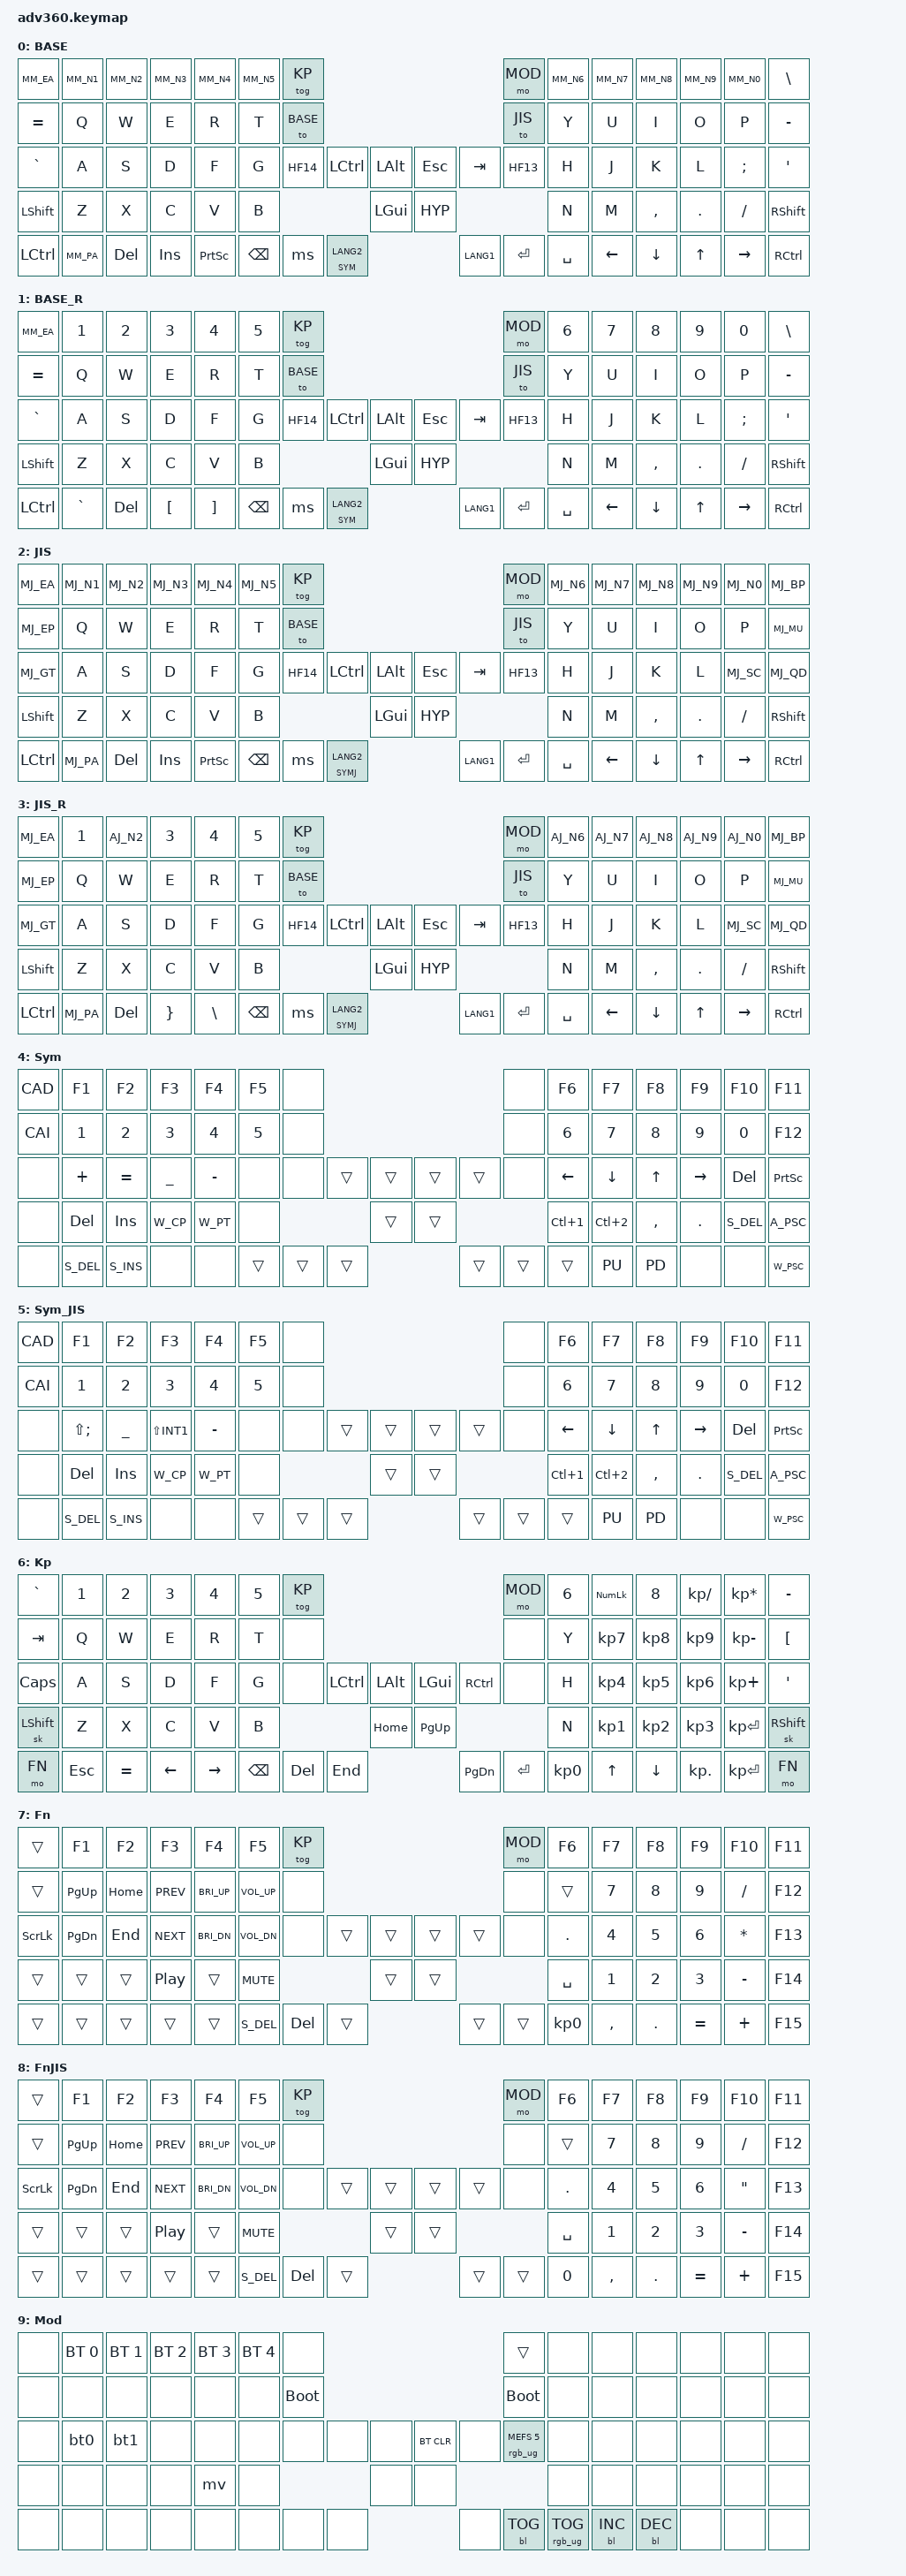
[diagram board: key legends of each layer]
#include <behaviors.dtsi>
#include <dt-bindings/zmk/keys.h>
#include <dt-bindings/zmk/bt.h>
#include <dt-bindings/zmk/rgb.h>
#include <dt-bindings/zmk/stp.h>
#include <dt-bindings/zmk/backlight.h>
#include <dt-bindings/zmk/pointing.h>

#include "include/adv360.h"
#include "include/helper.h"
#include "ansi-jis.dtsi"

#define BASE  0
#define BREV  1
#define JIS   2
#define JREV  3
#define SYM   4
#define SYMJ  5
#define KP    6
#define FN    7
#define FNJ   8
#define MOD   9

#define LCS LC(LSHFT)
#define RCS RC(RSHFT)
#define LCA LC(LALT)
#define RCA RC(RALT)
#define HYP LG(LA(LCTRL))
#define MEH LA(LS(LCTRL))
#define CAD LC(LA(DEL))
#define CAI LC(LA(INS))
#define ST  LG(TAB)
#define GG  LG(GRAVE)
#define HF13 LG(LA(LC(F13)))
#define HF14 LG(LA(LC(F14)))
#define W_CP LC(INS)
#define W_PT LS(INS)
#define C_PD LC(PG_DN)
#define C_PU LC(PG_UP)
#define A_PSC LA(PSCRN)
#define W_PSC LG(PSCRN)
#define S_DEL LS(DEL)
#define S_INS LS(INS)

#define BT0 &bt BT_SEL 0
#define BT1 &bt BT_SEL 1
#define BT2 &bt BT_SEL 2
#define BT3 &bt BT_SEL 3
#define BT4 &bt BT_SEL 4

#define XXX &none
#define ___ &trans

#define JRBR BSLS
#define JLBR RBRC

/* Global defaults */

#define QUICK_TAP_MS 175

&sk {
  release-after-ms = <200>;
  quick-release;
};

&sl { // Allow sticky mods to chord across sticky layers.
  ignore-modifiers;
};

&lt {
  flavor = "balanced";
  tapping-term-ms = <200>;
  // quick-tap-ms = <QUICK_TAP_MS>;
};

/* Magic-shift & auto-layers */

// Tap: repeat after alpha, else sticky-shift |
// Shift + tap/ double-tap: caps-word | Hold: shift.
/* #define ms &magic_shift LSHFT 0 */
/* ZMK_HOLD_TAP(magic_shift, bindings = <&kp>, <&magic_shift_tap>; */
/*              flavor = "balanced"; tapping-term-ms = <200>; */
/*              quick-tap-ms = <QUICK_TAP_MS>;) */
/* ZMK_MOD_MORPH(magic_shift_tap, bindings = <&shift_repeat>, <&caps_word>; */
/*               mods = <(MOD_LSFT)>;) */
/* ZMK_ADAPTIVE_KEY( */
/*     shift_repeat, bindings = <&sk LSHFT>; */
/*     repeat { */
/*       trigger-keys = <A B C D E F G H I J K L M N O P Q R S T U V W X Y Z 1 2 3 4 5 6 7 8 9>; */
/*       bindings = <&key_repeat>; */
/*       max-prior-idle-ms = <1200>; */
/*       strict-modifiers; */
/*     };) */
&caps_word { // Mods deactivate caps-word, requires PR #1451. [TODO: rebase]
  /delete-property/ ignore-modifiers;
  continue-list = <UNDERSCORE MINUS LS(INT1) BACKSPACE DELETE>;
};

/ {
    behaviors {
      #include "macros.dtsi"
      #include "version.dtsi"
      #include "switch_bt.dtsi"
      
      mv: macro_version {
        compatible = "zmk,behavior-macro";
        #binding-cells = <0>;
        bindings = <&kp RET>;
      };

      hm: homerow_mods {
          compatible = "zmk,behavior-hold-tap";
          #binding-cells = <2>;
          tapping-term-ms = <200>;
          quick_tap_ms = <180>;
          flavor = "tap-preferred";
          bindings = <&kp>, <&kp>;
      };

      ms: magic_shift {
        compatible = "zmk,behavior-tap-dance";
        #binding-cells = <0>;
        tapping-term-ms = <200>;
        bindings = <&sk LSHFT>, <&caps_word>;
      };

    };

    keymap {
        compatible = "zmk,keymap";

        default_layer {
          display-name = "BASE";
          bindings = <
            MM_EA     MM_N1 MM_N2   MM_N3    MM_N4     MM_N5 &tog KP                                                                 &mo MOD  MM_N6 MM_N7    MM_N8     MM_N9    MM_N0     &kp BSLH
            &kp EQUAL &kp Q &kp W   &kp E    &kp R     &kp T &to BASE                                                                &to JIS  &kp Y &kp U    &kp I     &kp O    &kp P     &kp MINUS
            &kp GRAVE &kp A &kp S   &kp D    &kp F     &kp G &kp HF14          &kp LCTRL &kp LALT      &kp ESC   &kp TAB             &kp HF13 &kp H &kp J    &kp K     &kp L    &kp SEMI  &kp SQT
            &kp LSHFT &kp Z &kp X   &kp C    &kp V     &kp B                             &kp LGUI      &kp HYP                                &kp N &kp M    &kp COMMA &kp DOT  &kp FSLH  &kp RSHFT
            &kp LCTRL MM_PA &kp DEL &kp INS &kp PSCRN                 &kp BSPC &ms       &lt SYM LANG2 &kp LANG1 &kp ENTER &kp SPACE                &kp LEFT &kp DOWN  &kp UP   &kp RIGHT &kp RCTRL
          >;
        };

        layer_default_reverse {
          display-name = "BASE_R";
          bindings = <
            MM_EA     &kp N1    &kp N2  &kp N3   &kp N4    &kp N5 &tog KP                                                                 &mo MOD  &kp N6 &kp N7   &kp N8    &kp N9  &kp N0    &kp BSLH
            &kp EQUAL &kp Q     &kp W   &kp E    &kp R     &kp T  &to BASE                                                                &to JIS  &kp Y  &kp U    &kp I     &kp O   &kp P     &kp MINUS
            &kp GRAVE &kp A     &kp S   &kp D    &kp F     &kp G  &kp HF14          &kp LCTRL &kp LALT      &kp ESC   &kp TAB             &kp HF13 &kp H  &kp J    &kp K     &kp L   &kp SEMI  &kp SQT
            &kp LSHFT &kp Z     &kp X   &kp C    &kp V     &kp B                              &kp LGUI      &kp HYP                                &kp N  &kp M    &kp COMMA &kp DOT &kp FSLH  &kp RSHFT
            &kp LCTRL &kp GRAVE &kp DEL &kp LBKT &kp RBKT                  &kp BSPC &ms       &lt SYM LANG2 &kp LANG1 &kp ENTER &kp SPACE                 &kp LEFT &kp DOWN  &kp UP  &kp RIGHT &kp RCTRL
          >;
        };

        layer_jis {
          display-name = "JIS";
          bindings = <
            MJ_EA     MJ_N1 MJ_N2   MJ_N3   MJ_N4     MJ_N5 &tog KP                                                                   &mo MOD  MJ_N6 MJ_N7    MJ_N8     MJ_N9   MJ_N0     MJ_BP
            MJ_EP     &kp Q &kp W   &kp E   &kp R     &kp T &to BASE                                                                  &to JIS  &kp Y &kp U    &kp I     &kp O   &kp P     MJ_MU
            MJ_GT     &kp A &kp S   &kp D   &kp F     &kp G &kp HF14          &kp LCTRL &kp LALT       &kp ESC   &kp TAB              &kp HF13 &kp H &kp J    &kp K     &kp L   MJ_SC     MJ_QD
            &kp LSHFT &kp Z &kp X   &kp C   &kp V     &kp B                             &kp LGUI       &kp HYP                                 &kp N &kp M    &kp COMMA &kp DOT &kp FSLH  &kp RSHFT
            &kp LCTRL MJ_PA &kp DEL &kp INS &kp PSCRN                &kp BSPC &ms       &lt SYMJ LANG2 &kp LANG1 &kp ENTER &kp SPACE                 &kp LEFT &kp DOWN  &kp UP  &kp RIGHT &kp RCTRL
          >;
        };

        layer_jis_reverse {
          display-name = "JIS_R";
          bindings = <
            MJ_EA     &kp N1 AJ_N2   &kp N3   &kp N4    &kp N5 &tog KP                                                                  &mo MOD  AJ_N6 AJ_N7    AJ_N8     AJ_N9   AJ_N0     MJ_BP
            MJ_EP     &kp Q  &kp W   &kp E    &kp R     &kp T  &to BASE                                                                 &to JIS  &kp Y &kp U    &kp I     &kp O   &kp P     MJ_MU
            MJ_GT     &kp A  &kp S   &kp D    &kp F     &kp G  &kp HF14          &kp LCTRL &kp LALT       &kp ESC   &kp TAB             &kp HF13 &kp H &kp J    &kp K     &kp L   MJ_SC     MJ_QD
            &kp LSHFT &kp Z  &kp X   &kp C    &kp V     &kp B                              &kp LGUI       &kp HYP                                &kp N &kp M    &kp COMMA &kp DOT &kp FSLH  &kp RSHFT
            &kp LCTRL MJ_PA  &kp DEL &kp RBRC &kp BSLH                  &kp BSPC &ms       &lt SYMJ LANG2 &kp LANG1 &kp ENTER &kp SPACE                &kp LEFT &kp DOWN  &kp UP  &kp RIGHT &kp RCTRL
          >;
        };

        layer_symbol {
          display-name = "Sym";
          bindings = <
            &kp CAD &kp F1    &kp F2    &kp F3    &kp F4    &kp F5 XXX                         XXX &kp F6     &kp F7     &kp F8    &kp F9    &kp F10   &kp F11
            &kp CAI &kp N1    &kp N2    &kp N3    &kp N4    &kp N5 XXX                         XXX &kp N6     &kp N7     &kp N8    &kp N9    &kp N0    &kp F12
            XXX     &kp PLUS  &kp EQUAL &kp UNDER &kp MINUS XXX    XXX     ___ ___ ___ ___     XXX &kp LEFT   &kp DOWN   &kp UP    &kp RIGHT &kp DEL   &kp PSCRN
            XXX     &kp DEL   &kp INS   &kp W_CP  &kp W_PT  XXX                ___ ___             &kp LC(N1) &kp LC(N2) &kp COMMA &kp DOT   &kp S_DEL &kp A_PSC
            XXX     &kp S_DEL &kp S_INS XXX       XXX                  ___ ___ ___ ___ ___ ___                &kp C_PU   &kp C_PD  XXX       XXX       &kp W_PSC
          >;
        };

        layer_symbol_with_jis {
          display-name = "Sym_JIS";
          bindings = <
            &kp CAD &kp F1       &kp F2    &kp F3       &kp F4    &kp F5 XXX                         XXX &kp F6     &kp F7     &kp F8    &kp F9    &kp F10   &kp F11
            &kp CAI &kp N1       &kp N2    &kp N3       &kp N4    &kp N5 XXX                         XXX &kp N6     &kp N7     &kp N8    &kp N9    &kp N0    &kp F12
            XXX     &kp LS(SEMI) &kp UNDER &kp LS(INT1) &kp MINUS XXX    XXX     ___ ___ ___ ___     XXX &kp LEFT   &kp DOWN   &kp UP    &kp RIGHT &kp DEL   &kp PSCRN
            XXX     &kp DEL      &kp INS   &kp W_CP     &kp W_PT  XXX                ___ ___             &kp LC(N1) &kp LC(N2) &kp COMMA &kp DOT   &kp S_DEL &kp A_PSC
            XXX     &kp S_DEL    &kp S_INS XXX          XXX                  ___ ___ ___ ___ ___ ___                &kp C_PU   &kp C_PD  XXX       XXX       &kp W_PSC
          >;
        };

        /* layer_symbol { */
        /*   display-name = "Sym"; */
        /*   bindings = < */
        /*     &kp GRAVE &kp F1    &kp F2    &kp F3    &kp F4   &kp F5    XXX                                                 XXX &kp F6   &kp F7   &kp F8   &kp F9    &kp F10   &kp F11 */
        /*     &kp AT    &kp COMMA &kp SQT   &kp DQT   &kp SEMI &kp QMARK XXX                                                 XXX XXX      XXX      XXX      XXX       &kp PSCRN &kp F12 */
        /*     &kp HASH  &kp CARET &kp EQUAL &kp UNDER &kp DLLR &kp STAR  XXX           XXX     ___ ___ XXX                   XXX &kp LEFT &kp DOWN &kp UP   &kp RIGHT &kp A_PSC &kp F13 */
        /*     &kp TILDE &kp LT    &kp PIPE  &kp MINUS &kp GT   &kp FSLH                        ___ ___                           XXX      XXX      &kp LT   &kp GT    &kp W_PSC &kp F14 */
        /*     XXX       XXX       XXX       XXX       XXX                    &kp S_DEL &kp DEL ___ ___ &kp LC(N2) &kp LC(N1)              &kp C_PU &kp C_PD XXX       XXX       &kp F15 */
        /*   >; */
        /* }; */

        layer_keypad {
          display-name = "Kp";
          bindings = <
            &kp GRAVE &kp N1  &kp N2    &kp N3   &kp N4    &kp N5 &tog KP                                                           &mo MOD &kp N6 &kp KP_NUM &kp N8    &kp KP_DIVIDE &kp KP_MULTIPLY &kp MINUS
            &kp TAB   &kp Q   &kp W     &kp E    &kp R     &kp T  XXX                                                               XXX     &kp Y  &kp KP_N7  &kp KP_N8 &kp KP_N9     &kp KP_MINUS    &kp LEFT_BRACKET
            &kp CAPS  &kp A   &kp S     &kp D    &kp F     &kp G  XXX            &kp LCTRL &kp LALT &kp LGUI  &kp RCTRL             XXX     &kp H  &kp KP_N4  &kp KP_N5 &kp KP_N6     &kp KP_PLUS     &kp SINGLE_QUOTE
            &sk LSHFT &kp Z   &kp X     &kp C    &kp V     &kp B                           &kp HOME &kp PG_UP                               &kp N  &kp KP_N1  &kp KP_N2 &kp KP_N3     &kp KP_ENTER    &sk RSHFT
            &mo FN    &kp ESC &kp EQUAL &kp LEFT &kp RIGHT                &kp BSPC &kp DEL &kp END  &kp PG_DN &kp ENTER &kp KP_N0                  &kp UP     &kp DOWN  &kp KP_DOT    &kp KP_ENTER    &mo FN
          >;
        };

        layer_fn {
          display-name = "Fn";
          bindings = <
            ___      &kp F1    &kp F2   &kp F3     &kp F4       &kp F5       &tog KP                                         &mo MOD &kp F6    &kp F7    &kp F8  &kp F9    &kp F10   &kp F11
            ___      &kp PG_UP &kp HOME &kp C_PREV &kp C_BRI_UP &kp C_VOL_UP XXX                                             XXX     ___       &kp N7    &kp N8  &kp N9    &kp FSLH  &kp F12
            &kp SLCK &kp PG_DN &kp END  &kp C_NEXT &kp C_BRI_DN &kp C_VOL_DN XXX               ___     ___ ___ ___           XXX     &kp DOT   &kp N4    &kp N5  &kp N6    &kp STAR  &kp F13
            ___      ___       ___      &kp C_PP   ___          &kp C_MUTE                             ___ ___                       &kp SPACE &kp N1    &kp N2  &kp N3    &kp MINUS &kp F14
            ___      ___       ___      ___        ___                               &kp S_DEL &kp DEL ___ ___ ___ &kp KP_N0                   &kp COMMA &kp DOT &kp EQUAL &kp PLUS  &kp F15
         >;
        };

        layer_fn_jis {
          display-name = "FnJIS";
          bindings = <
            ___      &kp F1    &kp F2   &kp F3     &kp F4       &kp F5       &tog KP                                       &mo MOD &kp F6    &kp F7    &kp F8  &kp F9    &kp F10   &kp F11
            ___      &kp PG_UP &kp HOME &kp C_PREV &kp C_BRI_UP &kp C_VOL_UP XXX                                           XXX     ___       &kp N7    &kp N8  &kp N9    &kp FSLH  &kp F12
            &kp SLCK &kp PG_DN &kp END  &kp C_NEXT &kp C_BRI_DN &kp C_VOL_DN XXX                ___     ___ ___ ___        XXX     &kp DOT   &kp N4    &kp N5  &kp N6    &kp DQT   &kp F13
            ___      ___       ___      &kp C_PP   ___          &kp C_MUTE                              ___ ___                    &kp SPACE &kp N1    &kp N2  &kp N3    &kp MINUS &kp F14
            ___      ___       ___      ___        ___                                &kp S_DEL &kp DEL ___ ___ ___ &kp N0                   &kp COMMA &kp DOT &kp EQUAL &kp PLUS  &kp F15
          >;
        };

        layer_mod {
          display-name = "Mod";
          bindings = <
            XXX BT0  BT1  BT2 BT3 BT4 XXX                                                           ___                    XXX  XXX        XXX        XXX XXX XXX
            XXX XXX  XXX  XXX XXX XXX &bootloader                                                   &bootloader            XXX  XXX        XXX        XXX XXX XXX
            XXX &bt0 &bt1 XXX XXX XXX XXX             XXX XXX &bt BT_CLR XXX                        &rgb_ug RGB_MEFS_CMD 5 XXX  XXX        XXX        XXX XXX XXX
            XXX XXX  XXX  XXX &mv XXX                     XXX XXX                                                          XXX  XXX        XXX        XXX XXX XXX
            XXX XXX  XXX  XXX XXX                 XXX XXX XXX XXX        &bl BL_TOG &rgb_ug RGB_TOG                             &bl BL_INC &bl BL_DEC XXX XXX XXX
          >;
        };

    };
};
